AUTOSAR XML (schema 00052)
standard types defined: boolean, float32, float64, sint32, sint16, sint8, uint32, uint16, uint8, void
package /AUTOSAR_Platform/ImplementationDataTypes
  36 x impl type, all with category=VALUE:
    Message1_ChkSum_IDT: base-type=Message1_ChkSum_sw_basetype
    Message1_Alvctr_IDT: base-type=Message1_Alvctr_sw_basetype
    Message1_DID_IDT: base-type=Message1_DID_sw_basetype
    Signal{4..7}_IDT: base-type=Signal{4..7}_sw_basetype
    Message2_ChkSum_IDT: base-type=Message2_ChkSum_sw_basetype
    Message2_Alvctr_IDT: base-type=Message2_Alvctr_sw_basetype
    Message2_DID_IDT: base-type=Message2_DID_sw_basetype
    Signal{8..15}_IDT: base-type=Signal{8..15}_sw_basetype
    Message4_ChkSum_IDT: base-type=Message4_ChkSum_sw_basetype
    Message4_Alvctr_IDT: base-type=Message4_Alvctr_sw_basetype
    Message4_DID_IDT: base-type=Message4_DID_sw_basetype
    Signal{16..19}_IDT: base-type=Signal{16..19}_sw_basetype
    Message5_ChkSum_IDT: base-type=Message5_ChkSum_sw_basetype
    Message5_Alvctr_IDT: base-type=Message5_Alvctr_sw_basetype
    Message5_DID_IDT: base-type=Message5_DID_sw_basetype
    Signal{20..27}_IDT: base-type=Signal{20..27}_sw_basetype
package /AUTOSAR_Platform/MemoryAddressMapping
  4 x sw addr method:
    CALIB: memory-allocation-keyword-policy=ADDR-METHOD-SHORT-NAME-AND-ALIGNMENT, section-type=CALPRM  # SwAddrMethod for normal variables (RAM).
    CODE: memory-allocation-keyword-policy=ADDR-METHOD-SHORT-NAME, section-type=CODE
    CONST: memory-allocation-keyword-policy=ADDR-METHOD-SHORT-NAME-AND-ALIGNMENT, section-type=CONST
    VAR: memory-allocation-keyword-policy=ADDR-METHOD-SHORT-NAME-AND-ALIGNMENT, section-type=VAR
package /System
  system System: category=SYSTEM_DESCRIPTION, system-version=1.0.0
    system mapping SystemMapping
      data-mappings:
        sender-receiver-to-signal-group-mapping={data-element=Core0.Core0_QM.OutputComp.RootSoftwareComposition.PP_Message1.Message1, signal-group=Message1, type-mapping=sender-rec-record-type-mapping=record-element-mappings=[{application-record-element=Message1_ChkSum_ADT, system-signal=Message1_ChkSum}, {application-record-element=Message1_Alvctr_ADT, system-signal=Message1_Alvctr}, {application-record-element=Message1_DID_ADT, system-signal=Message1_DID}, {application-record-element=Signal4_ADT, system-signal=Signal4}, {application-record-element=Signal5_ADT, system-signal=Signal5}, {application-record-element=Signal6_ADT, system-signal=Signal6}, {application-record-element=Signal7_ADT, system-signal=Signal7}]}
        sender-receiver-to-signal-group-mapping={data-element=Core0.Core0_QM.OutputComp.RootSoftwareComposition.PP_Message2.Message2, signal-group=Message2, type-mapping=sender-rec-record-type-mapping=record-element-mappings=[{application-record-element=Message2_ChkSum_ADT, system-signal=Message2_ChkSum}, {application-record-element=Message2_Alvctr_ADT, system-signal=Message2_Alvctr}, {application-record-element=Message2_DID_ADT, system-signal=Message2_DID}, {application-record-element=Signal8_ADT, system-signal=Signal8}, {application-record-element=Signal9_ADT, system-signal=Signal9}, {application-record-element=Signal10_ADT, system-signal=Signal10}, {application-record-element=Signal11_ADT, system-signal=Signal11}]}
        sender-receiver-to-signal-mapping={data-element=Core0.Core0_QM.OutputComp.RootSoftwareComposition.PP_Message3.Signal{12..15}, system-signal=Signal{12..15}}
        sender-receiver-to-signal-group-mapping={data-element=Core0.Core0_QM.InputComp.RootSoftwareComposition.RP_Message4.Message4, signal-group=Message4, type-mapping=sender-rec-record-type-mapping=record-element-mappings=[{application-record-element=Message4_ChkSum_ADT, system-signal=Message4_ChkSum}, {application-record-element=Message4_Alvctr_ADT, system-signal=Message4_Alvctr}, {application-record-element=Message4_DID_ADT, system-signal=Message4_DID}, {application-record-element=Signal16_ADT, system-signal=Signal16}, {application-record-element=Signal17_ADT, system-signal=Signal17}, {application-record-element=Signal18_ADT, system-signal=Signal18}, {application-record-element=Signal19_ADT, system-signal=Signal19}]}
        sender-receiver-to-signal-group-mapping={data-element=Core0.Core0_QM.InputComp.RootSoftwareComposition.RP_Message5.Message5, signal-group=Message5, type-mapping=sender-rec-record-type-mapping=record-element-mappings=[{application-record-element=Message5_ChkSum_ADT, system-signal=Message5_ChkSum}, {application-record-element=Message5_Alvctr_ADT, system-signal=Message5_Alvctr}, {application-record-element=Message5_DID_ADT, system-signal=Message5_DID}, {application-record-element=Signal20_ADT, system-signal=Signal20}, {application-record-element=Signal21_ADT, system-signal=Signal21}, {application-record-element=Signal22_ADT, system-signal=Signal22}, {application-record-element=Signal23_ADT, system-signal=Signal23}]}
        sender-receiver-to-signal-mapping={data-element=Core0.Core0_QM.InputComp.RootSoftwareComposition.RP_Message6.Signal{24..27}, system-signal=Signal{24..27}}
      sw-mappings:
        swc to ecu mapping Core0: component=RootSoftwareComposition.Core0, ecu-instance=ECU1
        swc to ecu mapping Core1: component=RootSoftwareComposition.Core1, ecu-instance=ECU1
    root-software-compositions:
      root sw composition prototype RootSoftwareComposition: software-composition=TopLevelComposition
package /CANInterfaces
  6 x sender receiver interface:
    Message1
      data Message1: type=Message1ADT
    Message2
      data Message2: type=Message2ADT
    Message3
      4 x data, all with sw-addr-method=VAR, sw-calibration-access=READ-ONLY:
        Signal{12..15}: type=Signal{12..15}_ADT
    Message4
      data Message4: type=Message4ADT
    Message5
      data Message5: type=Message5ADT
    Message6
      4 x data, all with sw-addr-method=VAR, sw-calibration-access=READ-ONLY:
        Signal24: type=Signal24_ADT  # Signal23
        Signal25: type=Signal25_ADT  # Signal24
        Signal26: type=Signal26_ADT  # Signal25
        Signal27: type=Signal27_ADT  # Signal26
package /Capgemini_Platform/ImplementationArrayDataTypes
  4 x impl type, all with category=ARRAY:
    uint8_5
      element uint8_5_Columns: array-size=5, array-size-semantics=FIXED-SIZE, implementation-data-type=uint8
    uint8_5_8
      element uint8_5_8_Columns: category=ARRAY, array-size=5, array-size-semantics=FIXED-SIZE
        element uint8_5_8_Rows: array-size=8, array-size-semantics=FIXED-SIZE, implementation-data-type=uint8
    uint32_10
      element uint32_10_Columns: array-size=10, array-size-semantics=FIXED-SIZE, implementation-data-type=uint32
    float32_10_6
      element float32_10_6_Columns: category=ARRAY, array-size=10, array-size-semantics=FIXED-SIZE
        element float32_10_6_Rows: array-size=6, array-size-semantics=FIXED-SIZE, implementation-data-type=float32
package /Capgemini_Platform/ImplementationRecordDataTypes
  6 x impl type, all with category=STRUCTURE:
    test_RecordDatatype
      element ele1: category=ARRAY
        element ele1_Columns: category=ARRAY, array-size=10, array-size-semantics=FIXED-SIZE
          element ele1_Rows: array-size=6, array-size-semantics=FIXED-SIZE, implementation-data-type=float32
      element ele2: category=VALUE, base-type=uint8
      element ele3: category=VALUE, base-type=uint32
    TestDT
      element ImplArrayDT: category=ARRAY
        element ImplArrayDT_Columns: category=ARRAY, array-size=10, array-size-semantics=FIXED-SIZE
          element ImplArrayDT_Rows: array-size=6, array-size-semantics=FIXED-SIZE, implementation-data-type=float32
      element ImplScalarDT: category=VALUE, base-type=uint8
      element test_RecordDatatype: category=STRUCTURE
        element ele1: category=ARRAY
          element ele1_Columns: category=ARRAY, array-size=10, array-size-semantics=FIXED-SIZE
            element ele1_Rows: array-size=6, array-size-semantics=FIXED-SIZE, implementation-data-type=float32
        element ele2: category=VALUE, base-type=uint8
        element ele3: category=VALUE, base-type=uint32
    Message1IDT
      7 x element, all with category=VALUE:
        Message1_ChkSum_IDT: base-type=Message1_ChkSum_sw_basetype
        Message1_Alvctr_IDT: base-type=Message1_Alvctr_sw_basetype
        Message1_DID_IDT: base-type=Message1_DID_sw_basetype
        Signal{4..7}_IDT: base-type=Signal{4..7}_sw_basetype
    Message2IDT
      7 x element, all with category=VALUE:
        Message2_ChkSum_IDT: base-type=Message2_ChkSum_sw_basetype
        Message2_Alvctr_IDT: base-type=Message2_Alvctr_sw_basetype
        Message2_DID_IDT: base-type=Message2_DID_sw_basetype
        Signal{8..11}_IDT: base-type=Signal{8..11}_sw_basetype
    Message4IDT
      7 x element, all with category=VALUE:
        Message4_ChkSum_IDT: base-type=Message4_ChkSum_sw_basetype
        Message4_Alvctr_IDT: base-type=Message4_Alvctr_sw_basetype
        Message4_DID_IDT: base-type=Message4_DID_sw_basetype
        Signal{16..19}_IDT: base-type=Signal{16..19}_sw_basetype
    Message5IDT
      7 x element, all with category=VALUE:
        Message5_ChkSum_IDT: base-type=Message5_ChkSum_sw_basetype
        Message5_Alvctr_IDT: base-type=Message5_Alvctr_sw_basetype
        Message5_DID_IDT: base-type=Message5_DID_sw_basetype
        Signal{20..23}_IDT: base-type=Signal{20..23}_sw_basetype
package /Capgemini_Platform/CompuMethods
  compu method Compu_TextTable: 0=Yes, 1=No
package /Capgemini_Platform/DataConstraints
  range DC_0_5: raw 0..5
package /Capgemini_Platform/Units
  41 x unit, all with factor-si-to-unit=1:
    NoUnit: display-name=Nounit  # Unit for dimensionless continuous value data types like numbers, factors, and coefficients
    Volt: display-name=V  # Voltage
    Current: display-name=A
    DegreeCelcius: display-name=°C  # Celcius
    DegreeFahrenheit: display-name=°F  # Fahrenheit
    Percentage: display-name=%
    Message1_Alvctr_Unit: display-name=NoUnit  # NoUnit
    Message1_DID_Unit: display-name=NoUnit  # NoUnit
    Signal4_Unit: display-name=V  # Voltage
    Signal5_Unit: display-name=A  # Current
    Signal6_Unit: display-name=°C  # Celcius
    Signal7_Unit: display-name=°F  # Fahrenheit
    Message2_ChkSum_Unit: display-name=NoUnit  # NoUnit
    Message2_Alvctr_Unit: display-name=NoUnit  # NoUnit
    Message2_DID_Unit: display-name=NoUnit  # NoUnit
    Signal8_Unit: display-name=V  # Voltage
    Signal9_Unit: display-name=A  # Current
    Signal10_Unit: display-name=°C  # Celcius
    Signal11_Unit: display-name=°F  # Fahrenheit
    Signal12_Unit: display-name=V  # Voltage
    Signal13_Unit: display-name=A  # Current
    Signal14_Unit: display-name=°C  # Celcius
    Signal15_Unit: display-name=°F  # Fahrenheit
    Message4_ChkSum_Unit: display-name=NoUnit  # NoUnit
    Message4_Alvctr_Unit: display-name=NoUnit  # NoUnit
    Message4_DID_Unit: display-name=NoUnit  # NoUnit
    Signal16_Unit: display-name=V  # Voltage
    Signal17_Unit: display-name=A  # Current
    Signal18_Unit: display-name=°C  # Celcius
    Signal19_Unit: display-name=°F  # Fahrenheit
    Message5_ChkSum_Unit: display-name=NoUnit  # NoUnit
    Message5_Alvctr_Unit: display-name=NoUnit  # NoUnit
    Message5_DID_Unit: display-name=NoUnit  # NoUnit
    Signal20_Unit: display-name=V  # Voltage
    Signal21_Unit: display-name=A  # Current
    Signal22_Unit: display-name=°C  # Celcius
    Signal23_Unit: display-name=°F  # Fahrenheit
    Signal24_Unit: display-name=V  # Voltage
    Signal25_Unit: display-name=A  # Current
    Signal26_Unit: display-name=°C  # Celcius
    Signal27_Unit: display-name=°F  # Fahrenheit
package /Capgemini_Platform/ApplicationDataTypes
  app type Element1_ADT: category=VALUE, sw-calibration-access=READ-WRITE, compu {phys=raw*5+0.5}, range raw 0..255, unit=A
  app type Element3_ADT: category=VALUE, sw-calibration-access=READ-WRITE, compu {phys=raw*5+0.5}, range raw 0..255, unit=A
  application array data type Element3_ADT_Columns: category=ARRAY
    element Element: category=VALUE, type=Element3_ADT_Rows, array-size-semantics=FIXED-SIZE, max-number-of-elements=5
  application array data type Element3_ADT_Rows: category=ARRAY
    element Element: category=VALUE, type=Element3_ADT, array-size-semantics=FIXED-SIZE, max-number-of-elements=8
  app type Element2_ADT: category=VALUE, sw-calibration-access=READ-WRITE, compu {phys=raw*5+0.5}, range raw 0..255, unit=A
  application array data type Element2_ADT_Columns: category=ARRAY
    element Element: category=VALUE, type=Element2_ADT_Rows, array-size-semantics=FIXED-SIZE, max-number-of-elements=5
  application array data type Element2_ADT_Rows: category=ARRAY
    element Element: category=VALUE, type=Element2_ADT, array-size-semantics=FIXED-SIZE, max-number-of-elements=8
  app type Element4_ADT: category=VALUE, sw-calibration-access=READ-WRITE, compu {phys=raw*5+0.5}, range raw 0..255, unit=A
  application array data type Element4_ADT_Columns: category=ARRAY
    element Element: category=VALUE, type=Element4_ADT_Rows, array-size-semantics=FIXED-SIZE, max-number-of-elements=5
  application array data type Element4_ADT_Rows: category=ARRAY
    element Element: category=VALUE, type=Element4_ADT, array-size-semantics=FIXED-SIZE, max-number-of-elements=8
  app type Element5_ADT: category=VALUE, sw-calibration-access=READ-WRITE, compu {phys=raw*5+0.5}, range raw 0..255, unit=A
  application array data type Element5_ADT_Columns: category=ARRAY
    element Element: category=VALUE, type=Element5_ADT_Rows, array-size-semantics=FIXED-SIZE, max-number-of-elements=5
  application array data type Element5_ADT_Rows: category=ARRAY
    element Element: category=VALUE, type=Element5_ADT, array-size-semantics=FIXED-SIZE, max-number-of-elements=8
  17 x app type, all with category=VALUE:
    Cureent_ADT: sw-calibration-access=READ-WRITE, compu {identical}, range raw 0..100, unit=A
    CANData_1_ADT: sw-calibration-access=READ-WRITE, compu {phys=0.01}, range raw 0..1, unit=%
    Current_ADT: sw-calibration-access=READ-WRITE, compu {identical}, range raw -3.4e+38..3.4e+38, unit=A
    Voltage_ADT: sw-calibration-access=READ-WRITE, compu {identical}, range raw -3.4e+38..3.4e+38, unit=V
    Cell_Voltage_ADT: sw-calibration-access=READ-WRITE, compu {identical}, range raw -3.4e+38..3.4e+38
    Current_Avg_ADT: sw-calibration-access=READ-WRITE, compu {identical}, range raw -3.4e+38..3.4e+38
    Voltage_OC_ADT: sw-calibration-access=READ-WRITE, compu {identical}, range raw -3.4e+38..3.4e+38
    Ccounter_NVStateOfCharge_ADT: sw-calibration-access=READ-WRITE, compu {identical}, range raw 0..255
    RecalSOC_NVStateOfCharge_ADT: sw-calibration-access=READ-WRITE, compu {identical}, range raw 0..255
    Op1Arg{1..3}_ADT: sw-calibration-access=READ-WRITE, compu {identical}, range raw 0..65535, unit=A
    Op2Arg{1..3}_ADT: sw-calibration-access=READ-WRITE, compu {identical}, range raw 0..65535, unit=A
    Param1_ADT: sw-calibration-access=READ-ONLY, compu {identical}, range raw 0..65535, unit=A
    Param2_ADT: sw-calibration-access=READ-WRITE, compu {identical}, range raw 0..4294967295, unit=A
  application array data type Param2_ADT_Columns: category=ARRAY
    element Element: category=VALUE, type=Param2_ADT, array-size-semantics=FIXED-SIZE, max-number-of-elements=10
  app type InputCompCANParam_ADT: category=VALUE, sw-calibration-access=READ-ONLY, compu {identical}, range raw 0..65535, unit=%
  application record data type ParamWithRecordDT_ADT: category=STRUCTURE, sw-calibration-access=READ-ONLY
    application record element ImplArrayDT: type=ImplArrayDT_ADT_Columns
    application record element ImplScalarDT: type=ImplScalarDT_ADT
    application record element test_RecordDatatype: type=test_RecordDatatype_ADT
  app type ImplArrayDT_ADT: category=VALUE, sw-calibration-access=READ-ONLY, compu {identical}, range raw -3.4e+38..3.4e+38, unit=V
  application array data type ImplArrayDT_ADT_Columns: category=ARRAY
    element Element: category=VALUE, type=ImplArrayDT_ADT_Rows, array-size-semantics=FIXED-SIZE, max-number-of-elements=10
  application array data type ImplArrayDT_ADT_Rows: category=ARRAY
    element Element: category=VALUE, type=ImplArrayDT_ADT, array-size-semantics=FIXED-SIZE, max-number-of-elements=6
  app type ImplScalarDT_ADT: category=VALUE, sw-calibration-access=READ-ONLY, compu {identical}, range raw 0..255, unit=V
  application record data type test_RecordDatatype_ADT: category=STRUCTURE, sw-calibration-access=READ-ONLY
    application record element ele1: type=ele1_ADT_Columns
    application record element ele2: type=ele2_ADT
    application record element ele3: type=ele3_ADT
  app type ele1_ADT: category=VALUE, sw-calibration-access=READ-ONLY, compu {identical}, range raw -3.4e+38..3.4e+38, unit=V
  application array data type ele1_ADT_Columns: category=ARRAY
    element Element: category=VALUE, type=ele1_ADT_Rows, array-size-semantics=FIXED-SIZE, max-number-of-elements=10
  application array data type ele1_ADT_Rows: category=ARRAY
    element Element: category=VALUE, type=ele1_ADT, array-size-semantics=FIXED-SIZE, max-number-of-elements=6
  12 x app type, all with category=VALUE, compu {identical}:
    ele2_ADT: sw-calibration-access=READ-ONLY, range raw 0..255, unit=V
    ele3_ADT: sw-calibration-access=READ-ONLY, range raw 0..4294967295, unit=V
    nominalCapacity_C_ADT: sw-calibration-access=READ-ONLY, range raw -3.4e+38..3.4e+38
    stateOfHealth_C_ADT: sw-calibration-access=READ-ONLY, range raw -3.4e+38..3.4e+38
    stateOfCharge_C_ADT: sw-calibration-access=READ-ONLY, range raw -3.4e+38..3.4e+38
    OCV_gra_C_ADT: sw-calibration-access=READ-ONLY, range raw -3.4e+38..3.4e+38
    IRV1_ADT: sw-calibration-access=READ-WRITE, range raw -32768..32767, unit=V
    IRV2_ADT: sw-calibration-access=READ-WRITE, range raw -3.4e+38..3.4e+38
    InputCompCAN_IRV_ADT: sw-calibration-access=READ-ONLY, range raw -3.4e+38..3.4e+38, unit=%
    PIM_Element1_ADT: sw-calibration-access=READ-WRITE, range raw -32768..32767, unit=V
    InputCompPIM_ADT: sw-calibration-access=READ-ONLY, range raw -32768..32767, unit=%
    StateOfHealth_ADT: sw-calibration-access=READ-WRITE, range raw 0..255
  application record data type Message1ADT: category=STRUCTURE, sw-calibration-access=READ-ONLY
    7 x application record element:
      Message1_ChkSum_ADT: type=Message1_ChkSum_ADT
      Message1_Alvctr_ADT: type=Message1_Alvctr_ADT
      Message1_DID_ADT: type=Message1_DID_ADT
      Signal{4..7}_ADT: type=Signal{4..7}_ADT
  7 x app type, all with category=VALUE, sw-calibration-access=READ-ONLY:
    Message1_ChkSum_ADT: compu {phys=raw*10+10}, range raw 0..50
    Message1_Alvctr_ADT: compu {phys=0.5}, range raw -100..100, unit=NoUnit
    Message1_DID_ADT: compu {phys=2}, range raw 0..1000, unit=NoUnit
    Signal4_ADT: compu {phys=raw*100+1}, range raw -5000..5000, unit=V
    Signal5_ADT: compu {identical}, range raw 0..100, unit=A
    Signal6_ADT: compu {identical}, range raw 0..100, unit=°C
    Signal7_ADT: compu {identical}, range raw 0..5000, unit=°F
  application record data type Message2ADT: category=STRUCTURE, sw-calibration-access=READ-ONLY
    7 x application record element:
      Message2_ChkSum_ADT: type=Message2_ChkSum_ADT
      Message2_Alvctr_ADT: type=Message2_Alvctr_ADT
      Message2_DID_ADT: type=Message2_DID_ADT
      Signal{8..11}_ADT: type=Signal{8..11}_ADT
  11 x app type, all with category=VALUE, sw-calibration-access=READ-ONLY:
    Message2_ChkSum_ADT: compu {phys=raw*10+10}, range raw 0..50, unit=NoUnit
    Message2_Alvctr_ADT: compu {phys=0.5}, range raw -100..100, unit=NoUnit
    Message2_DID_ADT: compu {phys=2}, range raw 0..1000, unit=NoUnit
    Signal8_ADT: compu {phys=raw*100+1}, range raw -5000..5000, unit=V
    Signal9_ADT: compu {identical}, range raw 0..100, unit=A
    Signal10_ADT: compu {identical}, range raw 0..100, unit=°C
    Signal11_ADT: compu {identical}, range raw 0..5000, unit=°F
    Signal12_ADT: compu {phys=raw*100+1}, range raw -5000..5000, unit=V
    Signal13_ADT: compu {identical}, range raw 0..100, unit=A
    Signal14_ADT: compu {identical}, range raw 0..100, unit=°C
    Signal15_ADT: compu {identical}, range raw 0..5000, unit=°F
  application record data type Message4ADT: category=STRUCTURE, sw-calibration-access=READ-ONLY
    7 x application record element:
      Message4_ChkSum_ADT: type=Message4_ChkSum_ADT
      Message4_Alvctr_ADT: type=Message4_Alvctr_ADT
      Message4_DID_ADT: type=Message4_DID_ADT
      Signal{16..19}_ADT: type=Signal{16..19}_ADT
  7 x app type, all with category=VALUE, sw-calibration-access=READ-ONLY:
    Message4_ChkSum_ADT: compu {phys=raw*10+10}, range raw 0..50, unit=NoUnit
    Message4_Alvctr_ADT: compu {phys=0.5}, range raw -100..100, unit=NoUnit
    Message4_DID_ADT: compu {phys=2}, range raw 0..1000, unit=NoUnit
    Signal16_ADT: compu {phys=raw*100+1}, range raw -5000..5000, unit=V
    Signal17_ADT: compu {identical}, range raw 0..100, unit=A
    Signal18_ADT: compu {identical}, range raw 0..100, unit=°C
    Signal19_ADT: compu {identical}, range raw 0..5000, unit=°F
  application record data type Message5ADT: category=STRUCTURE, sw-calibration-access=READ-ONLY
    7 x application record element:
      Message5_ChkSum_ADT: type=Message5_ChkSum_ADT
      Message5_Alvctr_ADT: type=Message5_Alvctr_ADT
      Message5_DID_ADT: type=Message5_DID_ADT
      Signal{20..23}_ADT: type=Signal{20..23}_ADT
  11 x app type, all with category=VALUE, sw-calibration-access=READ-ONLY:
    Message5_ChkSum_ADT: compu {phys=raw*10+10}, range raw 0..50, unit=NoUnit
    Message5_Alvctr_ADT: compu {phys=0.5}, range raw -100..100, unit=NoUnit
    Message5_DID_ADT: compu {phys=2}, range raw 0..1000, unit=NoUnit
    Signal20_ADT: compu {phys=raw*100+1}, range raw -5000..5000, unit=V
    Signal21_ADT: compu {identical}, range raw 0..100, unit=A
    Signal22_ADT: compu {identical}, range raw 0..100, unit=°C
    Signal23_ADT: compu {identical}, range raw 0..5000, unit=°F
    Signal24_ADT: compu {phys=raw*100+1}, range raw -5000..5000, unit=V
    Signal25_ADT: compu {identical}, range raw 0..100, unit=A
    Signal26_ADT: compu {identical}, range raw 0..100, unit=°C
    Signal27_ADT: compu {identical}, range raw 0..5000, unit=°F
package /Capgemini_Platform/InitValues
  13 x constant specification:
    Param1: value-spec=0 A
    Param2: value-spec=10 x 0 A
    InputCompCANParam: value-spec=50 %
    nominalCapacity_C: value-spec=0
    stateOfHealth_C: value-spec=0
    stateOfCharge_C: value-spec=0
    OCV_gra_C: value-spec=0
    IRV1: value-spec=0 V
    IRV2: value-spec=0
    InputCompCAN_IRV: value-spec=0 %
    PIM_Element1: value-spec=0 V
    InputCompPIM: value-spec=0 %
    StateOfHealth: value-spec=0
package /Capgemini_Platform/DataTypeMappingSet
  data type mapping set DataTypeMappingSet
    data-type-maps:
      application-data-type=Element1_ADT, implementation-data-type=uint8
      application-data-type=Element3_ADT_Columns, implementation-data-type=uint8_5_8
      application-data-type=Element2_ADT_Columns, implementation-data-type=uint8_5_8
      application-data-type=Element4_ADT_Columns, implementation-data-type=uint8_5_8
      application-data-type=Element5_ADT_Columns, implementation-data-type=uint8_5_8
      application-data-type=Cureent_ADT, implementation-data-type=float32
      application-data-type=CANData_1_ADT, implementation-data-type=uint8
      application-data-type=Current_ADT, implementation-data-type=float32
      application-data-type=Voltage_ADT, implementation-data-type=float32
      application-data-type=Cell_Voltage_ADT, implementation-data-type=float32
      application-data-type=Current_Avg_ADT, implementation-data-type=float32
      application-data-type=Voltage_OC_ADT, implementation-data-type=float32
      application-data-type=Ccounter_NVStateOfCharge_ADT, implementation-data-type=uint8
      application-data-type=RecalSOC_NVStateOfCharge_ADT, implementation-data-type=uint8
      application-data-type=Op1Arg{1..3}_ADT, implementation-data-type=uint16
      application-data-type=Op2Arg{1..3}_ADT, implementation-data-type=uint16
      application-data-type=Param1_ADT, implementation-data-type=uint16
      application-data-type=Param2_ADT_Columns, implementation-data-type=uint32_10
      application-data-type=InputCompCANParam_ADT, implementation-data-type=uint16
      application-data-type=ImplArrayDT_ADT_Columns, implementation-data-type=float32_10_6
      application-data-type=ImplScalarDT_ADT, implementation-data-type=uint8
      application-data-type=ele1_ADT_Columns, implementation-data-type=float32_10_6
      application-data-type=ele2_ADT, implementation-data-type=uint8
      application-data-type=ele3_ADT, implementation-data-type=uint32
      application-data-type=test_RecordDatatype_ADT, implementation-data-type=test_RecordDatatype
      application-data-type=ParamWithRecordDT_ADT, implementation-data-type=TestDT
      application-data-type=nominalCapacity_C_ADT, implementation-data-type=float32
      application-data-type=stateOfHealth_C_ADT, implementation-data-type=float32
      application-data-type=stateOfCharge_C_ADT, implementation-data-type=float32
      application-data-type=OCV_gra_C_ADT, implementation-data-type=float32
      application-data-type=IRV1_ADT, implementation-data-type=sint16
      application-data-type=IRV2_ADT, implementation-data-type=float32
      application-data-type=InputCompCAN_IRV_ADT, implementation-data-type=float32
      application-data-type=PIM_Element1_ADT, implementation-data-type=sint16
      application-data-type=InputCompPIM_ADT, implementation-data-type=sint16
      application-data-type=StateOfHealth_ADT, implementation-data-type=uint8
      application-data-type=Message1ADT, implementation-data-type=Message1IDT
      application-data-type=Message1_ChkSum_ADT, implementation-data-type=Message1_ChkSum_IDT
      application-data-type=Message1_Alvctr_ADT, implementation-data-type=Message1_Alvctr_IDT
      application-data-type=Message1_DID_ADT, implementation-data-type=Message1_DID_IDT
      application-data-type=Signal{4..7}_ADT, implementation-data-type=Signal{4..7}_IDT
      application-data-type=Message2ADT, implementation-data-type=Message2IDT
      application-data-type=Message2_ChkSum_ADT, implementation-data-type=Message2_ChkSum_IDT
      application-data-type=Message2_Alvctr_ADT, implementation-data-type=Message2_Alvctr_IDT
      application-data-type=Message2_DID_ADT, implementation-data-type=Message2_DID_IDT
      application-data-type=Signal{8..15}_ADT, implementation-data-type=Signal{8..15}_IDT
      application-data-type=Message4ADT, implementation-data-type=Message4IDT
      application-data-type=Message4_ChkSum_ADT, implementation-data-type=Message4_ChkSum_IDT
      application-data-type=Message4_Alvctr_ADT, implementation-data-type=Message4_Alvctr_IDT
      application-data-type=Message4_DID_ADT, implementation-data-type=Message4_DID_IDT
      application-data-type=Signal{16..19}_ADT, implementation-data-type=Signal{16..19}_IDT
      application-data-type=Message5ADT, implementation-data-type=Message5IDT
      application-data-type=Message5_ChkSum_ADT, implementation-data-type=Message5_ChkSum_IDT
      application-data-type=Message5_Alvctr_ADT, implementation-data-type=Message5_Alvctr_IDT
      application-data-type=Message5_DID_ADT, implementation-data-type=Message5_DID_IDT
      application-data-type=Signal{20..27}_ADT, implementation-data-type=Signal{20..27}_IDT
package /Root_Package/SWCs/Core0/QM/CompA
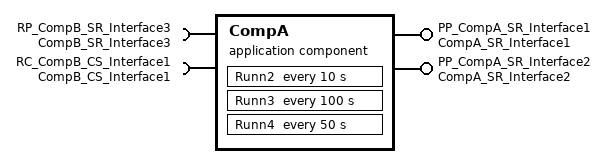
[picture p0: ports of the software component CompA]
  application sw component type CompA
    provide port PP_CompA_SR_Interface1: provided-interface=CompA_SR_Interface1
    provide port PP_CompA_SR_Interface2: provided-interface=CompA_SR_Interface2
    require port RP_CompB_SR_Interface3: required-interface=CompB_SR_Interface3
    require port RC_CompB_CS_Interface1: required-interface=CompB_CS_Interface1
    behavior CompA_InternalBehavior: data-type-mapping=DataTypeMappingSet, handle-termination-and-restart=NO-SUPPORT
      ar-typed-per-instance-memorys:
        data PIM_Element1: sw-addr-method=CALIB, sw-calibration-access=READ-WRITE, type=PIM_Element1_ADT, init-value=constant-reference=PIM_Element1  # Test1
      init event Runn1_InitEvent: start-on-event=Runn1
      timing event Runn2_TimingEvent_10ms: start-on-event=Runn2, period=10
      timing event Runn3_TimingEvent_100ms: start-on-event=Runn3, period=100
      timing event Runn4_TimingEvent_50ms: start-on-event=Runn4, period=50
      explicit-inter-runnable-variables:
        data IRV1: sw-addr-method=VAR, sw-calibration-access=READ-WRITE, type=IRV1_ADT, init-value=constant-reference=IRV1  # Test2
      per-instance-parameters:
        parameter data prototype Param1: sw-addr-method=CONST, sw-calibration-access=READ-ONLY, type=Param1_ADT, init-value=constant-reference=Param1  # ParamDesc1
        parameter data prototype Param2: sw-addr-method=CONST, sw-calibration-access=READ-WRITE, type=Param2_ADT_Columns, init-value=constant-reference=Param2  # ParamDesc2
      4 x runnable, all with sw-addr-method=CODE:
        Runn1: symbol=CompA_Runn1
        Runn2: symbol=CompA_Runn2
          data-read-access:
            access DRA_RP_CompB_SR_Interface3_Element4: accessed-variable=RP_CompB_SR_Interface3.Element4
          data-send-points:
            access DSP_PP_CompA_SR_Interface1_Element1: accessed-variable=PP_CompA_SR_Interface1.Element1
            access DSP_PP_CompA_SR_Interface1_Element3: accessed-variable=PP_CompA_SR_Interface1.Element3
            access DSP_PP_CompA_SR_Interface2_Element2: accessed-variable=PP_CompA_SR_Interface2.Element2
          parameter access PIPA_Param1: accessed-parameter=Param1
          parameter access PIPA_Param2: accessed-parameter=Param2
          written-local-variables:
            access IRVWA_IRV1: accessed-variable=IRV1
        Runn3: symbol=CompA_Runn3
          data-read-access:
            access DRA_RP_CompB_SR_Interface3_Element4: accessed-variable=RP_CompB_SR_Interface3.Element4
          data-send-points:
            access DSP_PP_CompA_SR_Interface2_Element2: accessed-variable=PP_CompA_SR_Interface2.Element2
          parameter access PIPA_Param1: accessed-parameter=Param1
          read-local-variables:
            access IRVRA_IRV1: accessed-variable=IRV1
          async call Operation2: operation=RC_CompB_CS_Interface1.Operation2, timeout=0
        Runn4: symbol=CompA_Runn4
          data-send-points:
            access DSP_PP_CompA_SR_Interface1_Element1: accessed-variable=PP_CompA_SR_Interface1.Element1
          sync call Operation1: operation=RC_CompB_CS_Interface1.Operation1, timeout=0
          async call Operation2: operation=RC_CompB_CS_Interface1.Operation2, timeout=0
  swc implementation CompA_Implementation: programming-language=C, sw-version=1.0.0, vendor-id=100, behavior=CompA_InternalBehavior
    code-descriptors:
      code CompA_CodeDescriptor: artifact-descriptors=autosar-engineering-object={short-label=CompA, category=SWSRC}
    resource consumption CompA_RC
      13 x memory section:
        VAR_8: alignment=8, sw-addrmethod=VAR
        VAR_16: alignment=16, sw-addrmethod=VAR
        VAR_32: alignment=32, sw-addrmethod=VAR
        VAR_UNSPECIFIED: sw-addrmethod=VAR
        CALIB_8: alignment=8, sw-addrmethod=CALIB
        CALIB_16: alignment=16, sw-addrmethod=CALIB
        CALIB_32: alignment=32, sw-addrmethod=CALIB
        CALIB_UNSPECIFIED: sw-addrmethod=CALIB
        CONST_8: alignment=8, sw-addrmethod=CONST
        CONST_16: alignment=16, sw-addrmethod=CONST
        CONST_32: alignment=32, sw-addrmethod=CONST
        CONST_UNSPECIFIED: sw-addrmethod=CONST
        CODE: sw-addrmethod=CODE
package /Root_Package/SWCs/Core0/QM/CompA/CompA_SRInterfaces
  sender receiver interface CompA_SR_Interface1
    data Element1: sw-addr-method=VAR, sw-calibration-access=READ-WRITE, type=Element1_ADT  # asd
    data Element3: sw-addr-method=VAR, sw-calibration-access=READ-WRITE, type=Element3_ADT_Columns  # Test4
  sender receiver interface CompA_SR_Interface2
    data Element2: sw-addr-method=VAR, sw-calibration-access=READ-WRITE, type=Element2_ADT_Columns  # Test3
package /Root_Package/SWCs/Core0/QM/CompB
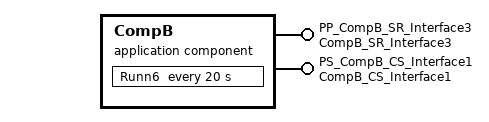
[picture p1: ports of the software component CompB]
  application sw component type CompB
    provide port PP_CompB_SR_Interface3: provided-interface=CompB_SR_Interface3
    provide port PS_CompB_CS_Interface1: provided-interface=CompB_CS_Interface1
    behavior CompB_InternalBehavior: data-type-mapping=DataTypeMappingSet, handle-termination-and-restart=NO-SUPPORT
      init event Runn5_InitEvent: start-on-event=Runn5
      timing event Runn6_TimingEvent_20ms: start-on-event=Runn6, period=20
      operation invoked event OIE_Runn7: start-on-event=Runn7, operation=PS_CompB_CS_Interface1.Operation1
      operation invoked event OIE_Runn15: start-on-event=Runn15, operation=PS_CompB_CS_Interface1.Operation2
      explicit-inter-runnable-variables:
        data IRV2: sw-addr-method=VAR, sw-calibration-access=READ-WRITE, type=IRV2_ADT, init-value=constant-reference=IRV2  # Test3
      per-instance-parameters:
        parameter data prototype ParamWithRecordDT: sw-addr-method=CONST, sw-calibration-access=READ-ONLY, type=ParamWithRecordDT_ADT  # ParamWithRecordDT_Description
      4 x runnable:
        Runn5: sw-addr-method=CODE, symbol=CompB_Runn5
          parameter access PIPA_ParamWithRecordDT: accessed-parameter=ParamWithRecordDT
          written-local-variables:
            access IRVWA_IRV2: accessed-variable=IRV2
        Runn6: sw-addr-method=CODE, symbol=CompB_Runn6
          data-write-access:
            access DWA_PP_CompB_SR_Interface3_Element4: accessed-variable=PP_CompB_SR_Interface3.Element4
          read-local-variables:
            access IRVRA_IRV2: accessed-variable=IRV2
        Runn7: symbol=CompB_Runn7
        Runn15: symbol=CompB_Runn15
  swc implementation CompB_Implementation: programming-language=C, sw-version=1.0.0, vendor-id=100, behavior=CompB_InternalBehavior
    code-descriptors:
      code CompB_CodeDescriptor: artifact-descriptors=autosar-engineering-object={short-label=CompB, category=SWSRC}
    resource consumption CompB_RC
      13 x memory section:
        VAR_8: alignment=8, sw-addrmethod=VAR
        VAR_16: alignment=16, sw-addrmethod=VAR
        VAR_32: alignment=32, sw-addrmethod=VAR
        VAR_UNSPECIFIED: sw-addrmethod=VAR
        CALIB_8: alignment=8, sw-addrmethod=CALIB
        CALIB_16: alignment=16, sw-addrmethod=CALIB
        CALIB_32: alignment=32, sw-addrmethod=CALIB
        CALIB_UNSPECIFIED: sw-addrmethod=CALIB
        CONST_8: alignment=8, sw-addrmethod=CONST
        CONST_16: alignment=16, sw-addrmethod=CONST
        CONST_32: alignment=32, sw-addrmethod=CONST
        CONST_UNSPECIFIED: sw-addrmethod=CONST
        CODE: sw-addrmethod=CODE
package /Root_Package/SWCs/Core0/QM/CompB/CompB_SRInterfaces
  sender receiver interface CompB_SR_Interface3
    data Element4: sw-addr-method=VAR, sw-calibration-access=READ-WRITE, type=Element4_ADT_Columns  # Test5
package /Root_Package/SWCs/Core0/QM/CompB/CompB_CSInterfaces
  client server interface CompB_CS_Interface1
    operation Operation1
      arg Op1Arg1: type=Op1Arg1_ADT, direction=IN
      arg Op1Arg2: type=Op1Arg2_ADT, direction=OUT
      arg Op1Arg3: type=Op1Arg3_ADT, direction=INOUT
    operation Operation2
      arg Op2Arg1: type=Op2Arg1_ADT, direction=IN  # Op1Arg1
      arg Op2Arg2: type=Op2Arg2_ADT, direction=OUT  # Op1Arg2
      arg Op2Arg3: type=Op2Arg3_ADT, direction=INOUT  # Op1Arg3
package /Root_Package/SWCs/Core0/QM/InputComp
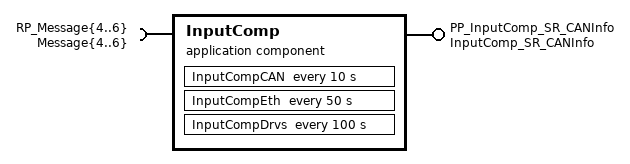
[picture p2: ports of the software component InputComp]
  application sw component type InputComp
    provide port PP_InputComp_SR_CANInfo: provided-interface=InputComp_SR_CANInfo
    require port RP_Message{4..6}: required-interface=Message{4..6}
    behavior InputComp_InternalBehavior: data-type-mapping=DataTypeMappingSet, handle-termination-and-restart=NO-SUPPORT
      ar-typed-per-instance-memorys:
        data InputCompPIM: sw-addr-method=CALIB, sw-calibration-access=READ-ONLY, type=InputCompPIM_ADT, init-value=constant-reference=InputCompPIM  # InputCompPIM_Description
      timing event InputCompCAN_TimingEvent_10ms: start-on-event=InputCompCAN, period=10
      timing event InputCompEth_TimingEvent_50ms: start-on-event=InputCompEth, period=50
      timing event InputCompDrvs_TimingEvent_100ms: start-on-event=InputCompDrvs, period=100
      init event InputCompInit_InitEvent: start-on-event=InputCompInit
      explicit-inter-runnable-variables:
        data InputCompCAN_IRV: sw-addr-method=VAR, sw-calibration-access=READ-ONLY, type=InputCompCAN_IRV_ADT, init-value=constant-reference=InputCompCAN_IRV  # InputCompCAN_IRV_Descriotion
      per-instance-parameters:
        parameter data prototype InputCompCANParam: sw-addr-method=CONST, sw-calibration-access=READ-ONLY, type=InputCompCANParam_ADT, init-value=constant-reference=InputCompCANParam  # InputCompCANParam_Decription
      4 x runnable, all with sw-addr-method=CODE:
        InputCompCAN: symbol=InputComp_InputCompCAN
          data-receive-point-by-arguments:
            6 x access:
              DRP_RP_Message4_Message4: accessed-variable=RP_Message4.Message4
              DRP_RP_Message5_Message5: accessed-variable=RP_Message5.Message5
              DRP_RP_Message6_Signal{24..27}: accessed-variable=RP_Message6.Signal{24..27}
          data-send-points:
            access DSP_PP_InputComp_SR_CANInfo_CANData_1: accessed-variable=PP_InputComp_SR_CANInfo.CANData_1
          parameter access PIPA_InputCompCANParam: accessed-parameter=InputCompCANParam
          written-local-variables:
            access IRVWA_InputCompCAN_IRV: accessed-variable=InputCompCAN_IRV
        InputCompEth: symbol=InputComp_InputCompEth
        InputCompDrvs: symbol=InputComp_InputCompDrvs
          read-local-variables:
            access IRVRA_InputCompCAN_IRV: accessed-variable=InputCompCAN_IRV
        InputCompInit: symbol=InputComp_InputCompInit
  swc implementation InputComp_Implementation: programming-language=C, sw-version=1.0.0, vendor-id=100, behavior=InputComp_InternalBehavior
    code-descriptors:
      code InputComp_CodeDescriptor: artifact-descriptors=autosar-engineering-object={short-label=InputComp, category=SWSRC}
    resource consumption InputComp_RC
      13 x memory section:
        VAR_8: alignment=8, sw-addrmethod=VAR
        VAR_16: alignment=16, sw-addrmethod=VAR
        VAR_32: alignment=32, sw-addrmethod=VAR
        VAR_UNSPECIFIED: sw-addrmethod=VAR
        CALIB_8: alignment=8, sw-addrmethod=CALIB
        CALIB_16: alignment=16, sw-addrmethod=CALIB
        CALIB_32: alignment=32, sw-addrmethod=CALIB
        CALIB_UNSPECIFIED: sw-addrmethod=CALIB
        CONST_8: alignment=8, sw-addrmethod=CONST
        CONST_16: alignment=16, sw-addrmethod=CONST
        CONST_32: alignment=32, sw-addrmethod=CONST
        CONST_UNSPECIFIED: sw-addrmethod=CONST
        CODE: sw-addrmethod=CODE
package /Root_Package/SWCs/Core0/QM/InputComp/InputComp_SRInterfaces
  sender receiver interface InputComp_SR_CANInfo
    data CANData_1: sw-addr-method=VAR, sw-calibration-access=READ-WRITE, type=CANData_1_ADT  # CANData_1_Description
package /Root_Package/SWCs/Core0/QM/OutputComp
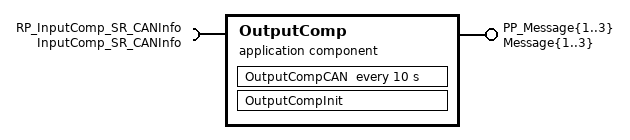
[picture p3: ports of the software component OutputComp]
  application sw component type OutputComp
    require port RP_InputComp_SR_CANInfo: required-interface=InputComp_SR_CANInfo
    provide port PP_Message{1..3}: provided-interface=Message{1..3}
    behavior OutputComp_InternalBehavior: data-type-mapping=DataTypeMappingSet, handle-termination-and-restart=NO-SUPPORT
      timing event OutputCompCAN_TimingEvent_10ms: start-on-event=OutputCompCAN, period=10
      init event OutputCompInit_InitEvent: start-on-event=OutputCompInit
      runnable OutputCompCAN: sw-addr-method=CODE, symbol=OutputComp_OutputCompCAN
        data-receive-point-by-arguments:
          access DRP_RP_InputComp_SR_CANInfo_CANData_1: accessed-variable=RP_InputComp_SR_CANInfo.CANData_1
        data-send-points:
          6 x access:
            DSP_PP_Message1_Message1: accessed-variable=PP_Message1.Message1
            DSP_PP_Message2_Message2: accessed-variable=PP_Message2.Message2
            DSP_PP_Message3_Signal{12..15}: accessed-variable=PP_Message3.Signal{12..15}
      runnable OutputCompInit: sw-addr-method=CODE, symbol=OutputComp_OutputCompInit
  swc implementation OutputComp_Implementation: programming-language=C, sw-version=1.0.0, vendor-id=100, behavior=OutputComp_InternalBehavior
    code-descriptors:
      code OutputComp_CodeDescriptor: artifact-descriptors=autosar-engineering-object={short-label=OutputComp, category=SWSRC}
    resource consumption OutputComp_RC
      13 x memory section:
        VAR_8: alignment=8, sw-addrmethod=VAR
        VAR_16: alignment=16, sw-addrmethod=VAR
        VAR_32: alignment=32, sw-addrmethod=VAR
        VAR_UNSPECIFIED: sw-addrmethod=VAR
        CALIB_8: alignment=8, sw-addrmethod=CALIB
        CALIB_16: alignment=16, sw-addrmethod=CALIB
        CALIB_32: alignment=32, sw-addrmethod=CALIB
        CALIB_UNSPECIFIED: sw-addrmethod=CALIB
        CONST_8: alignment=8, sw-addrmethod=CONST
        CONST_16: alignment=16, sw-addrmethod=CONST
        CONST_32: alignment=32, sw-addrmethod=CONST
        CONST_UNSPECIFIED: sw-addrmethod=CONST
        CODE: sw-addrmethod=CODE
package /Root_Package/SWCs/Core0/QM/Ccounter
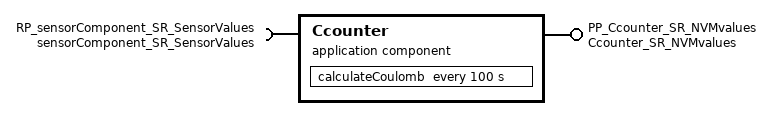
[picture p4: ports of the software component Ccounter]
  application sw component type Ccounter
    provide port PP_Ccounter_SR_NVMvalues: provided-interface=Ccounter_SR_NVMvalues
    require port RP_sensorComponent_SR_SensorValues: required-interface=sensorComponent_SR_SensorValues
    behavior Ccounter_InternalBehavior: data-type-mapping=DataTypeMappingSet, handle-termination-and-restart=NO-SUPPORT
      ar-typed-per-instance-memorys:
        data StateOfHealth: sw-addr-method=CALIB, sw-calibration-access=READ-WRITE, type=StateOfHealth_ADT, init-value=constant-reference=StateOfHealth
      timing event calculateCoulomb_TimingEvent_100ms: start-on-event=calculateCoulomb, period=100
      per-instance-parameters:
        parameter data prototype nominalCapacity_C: sw-addr-method=CONST, sw-calibration-access=READ-ONLY, type=nominalCapacity_C_ADT, init-value=constant-reference=nominalCapacity_C  # Nominal Capacity of Cells calibration
        parameter data prototype stateOfHealth_C: sw-addr-method=CONST, sw-calibration-access=READ-ONLY, type=stateOfHealth_C_ADT, init-value=constant-reference=stateOfHealth_C  # state of health calibration
        parameter data prototype stateOfCharge_C: sw-addr-method=CONST, sw-calibration-access=READ-ONLY, type=stateOfCharge_C_ADT, init-value=constant-reference=stateOfCharge_C  # state of charge calibration
      runnable calculateCoulomb: sw-addr-method=CODE, symbol=Ccounter_calculateCoulomb
        data-receive-point-by-arguments:
          access DRP_RP_sensorComponent_SR_SensorValues_Current: accessed-variable=RP_sensorComponent_SR_SensorValues.Current
          access DRP_RP_sensorComponent_SR_SensorValues_Voltage: accessed-variable=RP_sensorComponent_SR_SensorValues.Voltage
        data-send-points:
          access DSP_PP_Ccounter_SR_NVMvalues_Ccounter_NVStateOfCharge: accessed-variable=PP_Ccounter_SR_NVMvalues.Ccounter_NVStateOfCharge
        parameter access PIPA_nominalCapacity_C: accessed-parameter=nominalCapacity_C
        parameter access PIPA_stateOfHealth_C: accessed-parameter=stateOfHealth_C
        parameter access PIPA_stateOfCharge_C: accessed-parameter=stateOfCharge_C
  swc implementation Ccounter_Implementation: programming-language=C, sw-version=1.0.0, vendor-id=100, behavior=Ccounter_InternalBehavior
    code-descriptors:
      code Ccounter_CodeDescriptor: artifact-descriptors=autosar-engineering-object={short-label=Ccounter, category=SWSRC}
    resource consumption Ccounter_RC
      13 x memory section:
        VAR_8: alignment=8, sw-addrmethod=VAR
        VAR_16: alignment=16, sw-addrmethod=VAR
        VAR_32: alignment=32, sw-addrmethod=VAR
        VAR_UNSPECIFIED: sw-addrmethod=VAR
        CALIB_8: alignment=8, sw-addrmethod=CALIB
        CALIB_16: alignment=16, sw-addrmethod=CALIB
        CALIB_32: alignment=32, sw-addrmethod=CALIB
        CALIB_UNSPECIFIED: sw-addrmethod=CALIB
        CONST_8: alignment=8, sw-addrmethod=CONST
        CONST_16: alignment=16, sw-addrmethod=CONST
        CONST_32: alignment=32, sw-addrmethod=CONST
        CONST_UNSPECIFIED: sw-addrmethod=CONST
        CODE: sw-addrmethod=CODE
package /Root_Package/SWCs/Core0/QM/Ccounter/Ccounter_SRInterfaces
  sender receiver interface Ccounter_SR_NVMvalues
    data Ccounter_NVStateOfCharge: sw-addr-method=VAR, sw-calibration-access=READ-WRITE, type=Ccounter_NVStateOfCharge_ADT  # state of charge written to NVM
package /Root_Package/SWCs/Core0/QM/sensorComponent
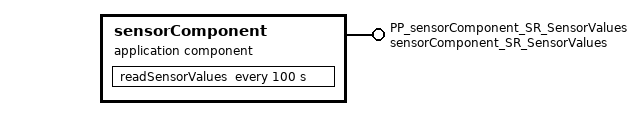
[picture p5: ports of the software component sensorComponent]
  application sw component type sensorComponent
    provide port PP_sensorComponent_SR_SensorValues: provided-interface=sensorComponent_SR_SensorValues
    behavior sensorComponent_InternalBehavior: data-type-mapping=DataTypeMappingSet, handle-termination-and-restart=NO-SUPPORT
      timing event readSensorValues_TimingEvent_100ms: start-on-event=readSensorValues, period=100
      runnable readSensorValues: sw-addr-method=CODE, symbol=sensorComponent_readSensorValues
        data-send-points:
          5 x access:
            DSP_PP_sensorComponent_SR_SensorValues_Current: accessed-variable=PP_sensorComponent_SR_SensorValues.Current
            DSP_PP_sensorComponent_SR_SensorValues_Voltage: accessed-variable=PP_sensorComponent_SR_SensorValues.Voltage
            DSP_PP_sensorComponent_SR_SensorValues_Cell_Voltage: accessed-variable=PP_sensorComponent_SR_SensorValues.Cell_Voltage
            DSP_PP_sensorComponent_SR_SensorValues_Current_Avg: accessed-variable=PP_sensorComponent_SR_SensorValues.Current_Avg
            DSP_PP_sensorComponent_SR_SensorValues_Voltage_OC: accessed-variable=PP_sensorComponent_SR_SensorValues.Voltage_OC
  swc implementation sensorComponent_Implementation: programming-language=C, sw-version=1.0.0, vendor-id=100, behavior=sensorComponent_InternalBehavior
    code-descriptors:
      code sensorComponent_CodeDescriptor: artifact-descriptors=autosar-engineering-object={short-label=sensorComponent, category=SWSRC}
    resource consumption sensorComponent_RC
      13 x memory section:
        VAR_8: alignment=8, sw-addrmethod=VAR
        VAR_16: alignment=16, sw-addrmethod=VAR
        VAR_32: alignment=32, sw-addrmethod=VAR
        VAR_UNSPECIFIED: sw-addrmethod=VAR
        CALIB_8: alignment=8, sw-addrmethod=CALIB
        CALIB_16: alignment=16, sw-addrmethod=CALIB
        CALIB_32: alignment=32, sw-addrmethod=CALIB
        CALIB_UNSPECIFIED: sw-addrmethod=CALIB
        CONST_8: alignment=8, sw-addrmethod=CONST
        CONST_16: alignment=16, sw-addrmethod=CONST
        CONST_32: alignment=32, sw-addrmethod=CONST
        CONST_UNSPECIFIED: sw-addrmethod=CONST
        CODE: sw-addrmethod=CODE
package /Root_Package/SWCs/Core0/QM/sensorComponent/sensorComponent_SRInterfaces
  sender receiver interface sensorComponent_SR_SensorValues
    5 x data, all with sw-addr-method=VAR, sw-calibration-access=READ-WRITE:
      Current: type=Current_ADT
      Voltage: type=Voltage_ADT
      Cell_Voltage: type=Cell_Voltage_ADT  # single cell voltage
      Current_Avg: type=Current_Avg_ADT  # average current measured
      Voltage_OC: type=Voltage_OC_ADT  # Open-Circuit voltage
package /Root_Package/SWCs/Core0/QM/RecalSOC
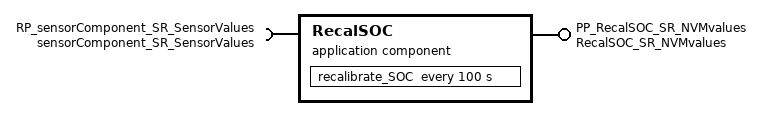
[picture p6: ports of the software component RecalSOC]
  application sw component type RecalSOC
    provide port PP_RecalSOC_SR_NVMvalues: provided-interface=RecalSOC_SR_NVMvalues
    require port RP_sensorComponent_SR_SensorValues: required-interface=sensorComponent_SR_SensorValues
    behavior RecalSOC_InternalBehavior: data-type-mapping=DataTypeMappingSet, handle-termination-and-restart=NO-SUPPORT
      timing event recalibrate_SOC_TimingEvent_100ms: start-on-event=recalibrate_SOC, period=100
      per-instance-parameters:
        parameter data prototype OCV_gra_C: sw-addr-method=CONST, sw-calibration-access=READ-ONLY, type=OCV_gra_C_ADT, init-value=constant-reference=OCV_gra_C  # Open-circuit voltage gradient
      runnable recalibrate_SOC: sw-addr-method=CODE, symbol=RecalSOC_recalibrate_SOC
        data-receive-point-by-arguments:
          access DRP_RP_sensorComponent_SR_SensorValues_Cell_Voltage: accessed-variable=RP_sensorComponent_SR_SensorValues.Cell_Voltage
          access DRP_RP_sensorComponent_SR_SensorValues_Current_Avg: accessed-variable=RP_sensorComponent_SR_SensorValues.Current_Avg
          access DRP_RP_sensorComponent_SR_SensorValues_Voltage_OC: accessed-variable=RP_sensorComponent_SR_SensorValues.Voltage_OC
        data-send-points:
          access DSP_PP_RecalSOC_SR_NVMvalues_RecalSOC_NVStateOfCharge: accessed-variable=PP_RecalSOC_SR_NVMvalues.RecalSOC_NVStateOfCharge
        parameter access PIPA_OCV_gra_C: accessed-parameter=OCV_gra_C
  swc implementation RecalSOC_Implementation: programming-language=C, sw-version=1.0.0, vendor-id=100, behavior=RecalSOC_InternalBehavior
    code-descriptors:
      code RecalSOC_CodeDescriptor: artifact-descriptors=autosar-engineering-object={short-label=RecalSOC, category=SWSRC}
    resource consumption RecalSOC_RC
      13 x memory section:
        VAR_8: alignment=8, sw-addrmethod=VAR
        VAR_16: alignment=16, sw-addrmethod=VAR
        VAR_32: alignment=32, sw-addrmethod=VAR
        VAR_UNSPECIFIED: sw-addrmethod=VAR
        CALIB_8: alignment=8, sw-addrmethod=CALIB
        CALIB_16: alignment=16, sw-addrmethod=CALIB
        CALIB_32: alignment=32, sw-addrmethod=CALIB
        CALIB_UNSPECIFIED: sw-addrmethod=CALIB
        CONST_8: alignment=8, sw-addrmethod=CONST
        CONST_16: alignment=16, sw-addrmethod=CONST
        CONST_32: alignment=32, sw-addrmethod=CONST
        CONST_UNSPECIFIED: sw-addrmethod=CONST
        CODE: sw-addrmethod=CODE
package /Root_Package/SWCs/Core0/QM/RecalSOC/RecalSOC_SRInterfaces
  sender receiver interface RecalSOC_SR_NVMvalues
    data RecalSOC_NVStateOfCharge: sw-addr-method=VAR, sw-calibration-access=READ-WRITE, type=RecalSOC_NVStateOfCharge_ADT  # state of charge written to NVM
package /Root_Package/SWCs/Core0/ASILB/CompE
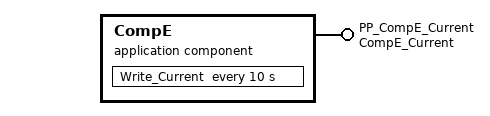
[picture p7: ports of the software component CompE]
  application sw component type CompE
    provide port PP_CompE_Current: provided-interface=CompE_Current
    behavior CompE_InternalBehavior: data-type-mapping=DataTypeMappingSet, handle-termination-and-restart=NO-SUPPORT
      timing event Write_Current_TimingEvent_10ms: start-on-event=Write_Current, period=10
      runnable Write_Current: sw-addr-method=CODE, symbol=CompE_Write_Current
        data-send-points:
          access DSP_PP_CompE_Current_Cureent: accessed-variable=PP_CompE_Current.Cureent
  swc implementation CompE_Implementation: programming-language=C, sw-version=1.0.0, vendor-id=100, behavior=CompE_InternalBehavior
    code-descriptors:
      code CompE_CodeDescriptor: artifact-descriptors=autosar-engineering-object={short-label=CompE, category=SWSRC}
    resource consumption CompE_RC
      13 x memory section:
        VAR_8: alignment=8, sw-addrmethod=VAR
        VAR_16: alignment=16, sw-addrmethod=VAR
        VAR_32: alignment=32, sw-addrmethod=VAR
        VAR_UNSPECIFIED: sw-addrmethod=VAR
        CALIB_8: alignment=8, sw-addrmethod=CALIB
        CALIB_16: alignment=16, sw-addrmethod=CALIB
        CALIB_32: alignment=32, sw-addrmethod=CALIB
        CALIB_UNSPECIFIED: sw-addrmethod=CALIB
        CONST_8: alignment=8, sw-addrmethod=CONST
        CONST_16: alignment=16, sw-addrmethod=CONST
        CONST_32: alignment=32, sw-addrmethod=CONST
        CONST_UNSPECIFIED: sw-addrmethod=CONST
        CODE: sw-addrmethod=CODE
package /Root_Package/SWCs/Core0/ASILB/CompE/CompE_SRInterfaces
  sender receiver interface CompE_Current
    data Cureent: sw-addr-method=VAR, sw-calibration-access=READ-WRITE, type=Cureent_ADT  # sdf
package /Root_Package/SWCs/Core1/QM/CompC
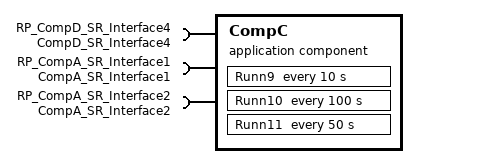
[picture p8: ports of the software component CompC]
  application sw component type CompC
    require port RP_CompD_SR_Interface4: required-interface=CompD_SR_Interface4
    require port RP_CompA_SR_Interface1: required-interface=CompA_SR_Interface1
    require port RP_CompA_SR_Interface2: required-interface=CompA_SR_Interface2
    behavior CompC_InternalBehavior: data-type-mapping=DataTypeMappingSet, handle-termination-and-restart=NO-SUPPORT
      init event Runn8_InitEvent: start-on-event=Runn8
      timing event Runn9_TimingEvent_10ms: start-on-event=Runn9, period=10
      timing event Runn10_TimingEvent_100ms: start-on-event=Runn10, period=100
      timing event Runn11_TimingEvent_50ms: start-on-event=Runn11, period=50
      4 x runnable, all with sw-addr-method=CODE:
        Runn{8..10}: symbol=CompC_Runn{8..10}
        Runn11: symbol=CompC_Runn11
          data-read-access:
            access DRA_RP_CompD_SR_Interface4_Element5: accessed-variable=RP_CompD_SR_Interface4.Element5
          data-receive-point-by-arguments:
            access DRP_RP_CompA_SR_Interface1_Element1: accessed-variable=RP_CompA_SR_Interface1.Element1
            access DRP_RP_CompA_SR_Interface2_Element2: accessed-variable=RP_CompA_SR_Interface2.Element2
  swc implementation CompC_Implementation: programming-language=C, sw-version=1.0.0, vendor-id=100, behavior=CompC_InternalBehavior
    code-descriptors:
      code CompC_CodeDescriptor: artifact-descriptors=autosar-engineering-object={short-label=CompC, category=SWSRC}
    resource consumption CompC_RC
      13 x memory section:
        VAR_8: alignment=8, sw-addrmethod=VAR
        VAR_16: alignment=16, sw-addrmethod=VAR
        VAR_32: alignment=32, sw-addrmethod=VAR
        VAR_UNSPECIFIED: sw-addrmethod=VAR
        CALIB_8: alignment=8, sw-addrmethod=CALIB
        CALIB_16: alignment=16, sw-addrmethod=CALIB
        CALIB_32: alignment=32, sw-addrmethod=CALIB
        CALIB_UNSPECIFIED: sw-addrmethod=CALIB
        CONST_8: alignment=8, sw-addrmethod=CONST
        CONST_16: alignment=16, sw-addrmethod=CONST
        CONST_32: alignment=32, sw-addrmethod=CONST
        CONST_UNSPECIFIED: sw-addrmethod=CONST
        CODE: sw-addrmethod=CODE
package /Root_Package/SWCs/Core1/ASILA/CompD
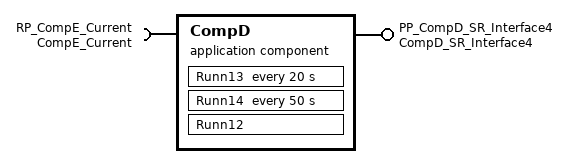
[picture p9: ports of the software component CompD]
  application sw component type CompD
    provide port PP_CompD_SR_Interface4: provided-interface=CompD_SR_Interface4
    require port RP_CompE_Current: required-interface=CompE_Current
    behavior CompD_InternalBehavior: data-type-mapping=DataTypeMappingSet, handle-termination-and-restart=NO-SUPPORT
      init event Runn12_InitEvent: start-on-event=Runn12
      timing event Runn13_TimingEvent_20ms: start-on-event=Runn13, period=20
      timing event Runn14_TimingEvent_50ms: start-on-event=Runn14, period=50
      runnable Runn12: sw-addr-method=CODE, symbol=CompD_Runn12
      runnable Runn13: sw-addr-method=CODE, symbol=CompD_Runn13
      runnable Runn14: sw-addr-method=CODE, symbol=CompD_Runn14
        data-receive-point-by-arguments:
          access DRP_RP_CompE_Current_Cureent: accessed-variable=RP_CompE_Current.Cureent
        data-write-access:
          access DWA_PP_CompD_SR_Interface4_Element5: accessed-variable=PP_CompD_SR_Interface4.Element5
  swc implementation CompD_Implementation: programming-language=C, sw-version=1.0.0, vendor-id=100, behavior=CompD_InternalBehavior
    code-descriptors:
      code CompD_CodeDescriptor: artifact-descriptors=autosar-engineering-object={short-label=CompD, category=SWSRC}
    resource consumption CompD_RC
      13 x memory section:
        VAR_8: alignment=8, sw-addrmethod=VAR
        VAR_16: alignment=16, sw-addrmethod=VAR
        VAR_32: alignment=32, sw-addrmethod=VAR
        VAR_UNSPECIFIED: sw-addrmethod=VAR
        CALIB_8: alignment=8, sw-addrmethod=CALIB
        CALIB_16: alignment=16, sw-addrmethod=CALIB
        CALIB_32: alignment=32, sw-addrmethod=CALIB
        CALIB_UNSPECIFIED: sw-addrmethod=CALIB
        CONST_8: alignment=8, sw-addrmethod=CONST
        CONST_16: alignment=16, sw-addrmethod=CONST
        CONST_32: alignment=32, sw-addrmethod=CONST
        CONST_UNSPECIFIED: sw-addrmethod=CONST
        CODE: sw-addrmethod=CODE
package /Root_Package/SWCs/Core1/ASILA/CompD/CompD_SRInterfaces
  sender receiver interface CompD_SR_Interface4
    data Element5: sw-addr-method=VAR, sw-calibration-access=READ-WRITE, type=Element5_ADT_Columns  # Test5
package /Root_Package/TopLevelComposition
  composition sw component type TopLevelComposition
    component Core0: type=Core0
    component Core1: type=Core1
    connect Core0.PP_CompA_SR_Interface1 -> Core1.RP_CompA_SR_Interface1
    connect Core0.PP_CompA_SR_Interface2 -> Core1.RP_CompA_SR_Interface2
    connect Core0.PP_CompE_Current -> Core1.RP_CompE_Current
package /Root_Package/TopLevelComposition/CoreCompositions
  composition sw component type Core0
    8 x provide port:
      PP_CompA_SR_Interface1: provided-interface=CompA_SR_Interface1
      PP_CompA_SR_Interface2: provided-interface=CompA_SR_Interface2
      PP_Message{1..3}: provided-interface=Message{1..3}
      PP_Ccounter_SR_NVMvalues: provided-interface=Ccounter_SR_NVMvalues
      PP_RecalSOC_SR_NVMvalues: provided-interface=RecalSOC_SR_NVMvalues
      PP_CompE_Current: provided-interface=CompE_Current
    4 x require port:
      RP_Message{4..6}: required-interface=Message{4..6}
      RP_sensorComponent_SR_SensorValues: required-interface=sensorComponent_SR_SensorValues
    component Core0_QM: type=Core0_QM
    component Core0_ASILB: type=Core0_ASILB
    delegate Core0_QM.PP_CompA_SR_Interface1 <-> outer port Core0/PP_CompA_SR_Interface1
    delegate Core0_QM.PP_CompA_SR_Interface2 <-> outer port Core0/PP_CompA_SR_Interface2
    delegate Core0_QM.PP_Message{1..3} <-> outer port Core0/PP_Message{1..3}
    delegate Core0_QM.PP_Ccounter_SR_NVMvalues <-> outer port Core0/PP_Ccounter_SR_NVMvalues
    delegate Core0_QM.PP_RecalSOC_SR_NVMvalues <-> outer port Core0/PP_RecalSOC_SR_NVMvalues
    delegate Core0_ASILB.PP_CompE_Current <-> outer port Core0/PP_CompE_Current
    delegate Core0_QM.RP_Message{4..6} <-> outer port Core0/RP_Message{4..6}
    delegate Core0_QM.RP_sensorComponent_SR_SensorValues <-> outer port Core0/RP_sensorComponent_SR_SensorValues
  composition sw component type Core1
    require port RP_CompA_SR_Interface1: required-interface=CompA_SR_Interface1
    require port RP_CompA_SR_Interface2: required-interface=CompA_SR_Interface2
    require port RP_CompE_Current: required-interface=CompE_Current
    component Core1_QM: type=Core1_QM
    component Core1_ASILA: type=Core1_ASILA
    connect Core1_ASILA.PP_CompD_SR_Interface4 -> Core1_QM.RP_CompD_SR_Interface4
    delegate Core1_QM.RP_CompA_SR_Interface1 <-> outer port Core1/RP_CompA_SR_Interface1
    delegate Core1_QM.RP_CompA_SR_Interface2 <-> outer port Core1/RP_CompA_SR_Interface2
    delegate Core1_ASILA.RP_CompE_Current <-> outer port Core1/RP_CompE_Current
package /Root_Package/TopLevelComposition/ASILCompositions
  composition sw component type Core0_QM
    7 x provide port:
      PP_CompA_SR_Interface1: provided-interface=CompA_SR_Interface1
      PP_CompA_SR_Interface2: provided-interface=CompA_SR_Interface2
      PP_Message{1..3}: provided-interface=Message{1..3}
      PP_Ccounter_SR_NVMvalues: provided-interface=Ccounter_SR_NVMvalues
      PP_RecalSOC_SR_NVMvalues: provided-interface=RecalSOC_SR_NVMvalues
    4 x require port:
      RP_Message{4..6}: required-interface=Message{4..6}
      RP_sensorComponent_SR_SensorValues: required-interface=sensorComponent_SR_SensorValues
    7 x component:
      CompA: type=CompA
      CompB: type=CompB
      InputComp: type=InputComp
      OutputComp: type=OutputComp
      Ccounter: type=Ccounter
      sensorComponent: type=sensorComponent
      RecalSOC: type=RecalSOC
    delegate CompA.PP_CompA_SR_Interface1 <-> outer port Core0_QM/PP_CompA_SR_Interface1
    delegate CompA.PP_CompA_SR_Interface2 <-> outer port Core0_QM/PP_CompA_SR_Interface2
    connect CompB.PP_CompB_SR_Interface3 -> CompA.RP_CompB_SR_Interface3
    connect CompB.PS_CompB_CS_Interface1 -> CompA.RC_CompB_CS_Interface1
    connect InputComp.PP_InputComp_SR_CANInfo -> OutputComp.RP_InputComp_SR_CANInfo
    delegate OutputComp.PP_Message{1..3} <-> outer port Core0_QM/PP_Message{1..3}
    delegate Ccounter.PP_Ccounter_SR_NVMvalues <-> outer port Core0_QM/PP_Ccounter_SR_NVMvalues
    connect sensorComponent.PP_sensorComponent_SR_SensorValues -> Ccounter.RP_sensorComponent_SR_SensorValues
    delegate RecalSOC.PP_RecalSOC_SR_NVMvalues <-> outer port Core0_QM/PP_RecalSOC_SR_NVMvalues
    delegate InputComp.RP_Message{4..6} <-> outer port Core0_QM/RP_Message{4..6}
    delegate RecalSOC.RP_sensorComponent_SR_SensorValues <-> outer port Core0_QM/RP_sensorComponent_SR_SensorValues
  composition sw component type Core0_ASILB
    provide port PP_CompE_Current: provided-interface=CompE_Current
    component CompE: type=CompE
    delegate CompE.PP_CompE_Current <-> outer port Core0_ASILB/PP_CompE_Current
  composition sw component type Core1_QM
    require port RP_CompD_SR_Interface4: required-interface=CompD_SR_Interface4
    require port RP_CompA_SR_Interface1: required-interface=CompA_SR_Interface1
    require port RP_CompA_SR_Interface2: required-interface=CompA_SR_Interface2
    component CompC: type=CompC
    delegate CompC.RP_CompD_SR_Interface4 <-> outer port Core1_QM/RP_CompD_SR_Interface4
    delegate CompC.RP_CompA_SR_Interface1 <-> outer port Core1_QM/RP_CompA_SR_Interface1
    delegate CompC.RP_CompA_SR_Interface2 <-> outer port Core1_QM/RP_CompA_SR_Interface2
  composition sw component type Core1_ASILA
    provide port PP_CompD_SR_Interface4: provided-interface=CompD_SR_Interface4
    require port RP_CompE_Current: required-interface=CompE_Current
    component CompD: type=CompD
    delegate CompD.PP_CompD_SR_Interface4 <-> outer port Core1_ASILA/PP_CompD_SR_Interface4
    delegate CompD.RP_CompE_Current <-> outer port Core1_ASILA/RP_CompE_Current
package /CANCatalog/Cluster
  can cluster CAN_Bus_Cluster: baudrate=500000, protocol-name=CAN
    can physical channel CAN_Bus_Channel: comm-connectors=[ECU1_CanCommunicationConnector, ECU2_CanCommunicationConnector, ECU3_CanCommunicationConnector]
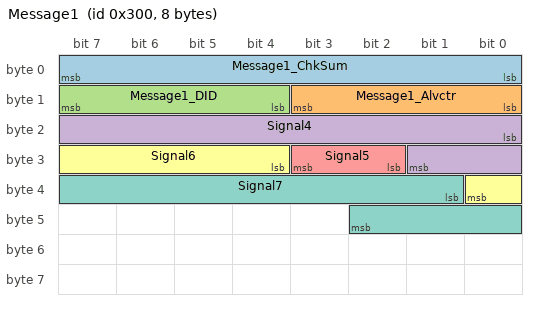
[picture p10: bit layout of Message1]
      frame Message1: id 0x300, from ECU1, to ECU2, frame-length=8, can-addressing-mode=EXTENDED, can-frame-rx-behavior=CAN-FD, can-frame-tx-behavior=CAN-FD
        pdu Message1: length=8, transmission-mode-true-timing=cyclic-timing=time-period=10, unused-bit-pattern=255
          mapping Message1_Message1Group: i-signal-group=Message1, packing-byte-order=little-endian
          signal Message1_ChkSum: start 0, 8 bit, little-endian, data-type-policy=OVERRIDE, base-type=Message1_ChkSum_sw_basetype, compu {phys=raw*10+10}, range raw 0..50
          signal Message1_Alvctr: start 8, 4 bit, little-endian, data-type-policy=OVERRIDE, base-type=Message1_Alvctr_sw_basetype, compu {phys=0.5}, range raw -100..100, unit=NoUnit
          signal Message1_DID: start 12, 4 bit, little-endian, data-type-policy=OVERRIDE, base-type=Message1_DID_sw_basetype, compu {phys=2}, range raw 0..1000, unit=NoUnit
          signal Signal4: start 16, 10 bit, little-endian, data-type-policy=OVERRIDE, base-type=Signal4_sw_basetype, compu {phys=raw*100+1}, range raw -5000..5000, unit=V
          signal Signal5: start 26, 2 bit, little-endian, data-type-policy=OVERRIDE, base-type=Signal5_sw_basetype, compu {identical}, range raw 0..100, unit=A
          signal Signal6: start 28, 5 bit, little-endian, data-type-policy=OVERRIDE, base-type=Signal6_sw_basetype, compu {identical}, range raw 0..100, unit=°C
          signal Signal7: start 33, 10 bit, little-endian, data-type-policy=OVERRIDE, base-type=Signal7_sw_basetype, compu {identical}, range raw 0..5000, unit=°F
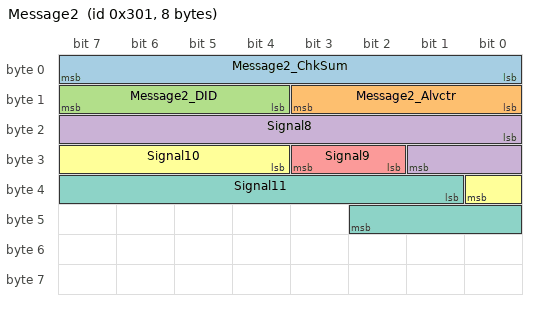
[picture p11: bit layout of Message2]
      frame Message2: id 0x301, from ECU1, to ECU2, frame-length=8, can-addressing-mode=EXTENDED, can-frame-rx-behavior=CAN-FD, can-frame-tx-behavior=CAN-FD
        pdu Message2: length=8, transmission-mode-true-timing=cyclic-timing=time-period=10, unused-bit-pattern=255
          mapping Message2_Message2Group: i-signal-group=Message2, packing-byte-order=little-endian
          signal Message2_ChkSum: start 0, 8 bit, little-endian, data-type-policy=OVERRIDE, base-type=Message2_ChkSum_sw_basetype, compu {phys=raw*10+10}, range raw 0..50, unit=NoUnit
          signal Message2_Alvctr: start 8, 4 bit, little-endian, data-type-policy=OVERRIDE, base-type=Message2_Alvctr_sw_basetype, compu {phys=0.5}, range raw -100..100, unit=NoUnit
          signal Message2_DID: start 12, 4 bit, little-endian, data-type-policy=OVERRIDE, base-type=Message2_DID_sw_basetype, compu {phys=2}, range raw 0..1000, unit=NoUnit
          signal Signal8: start 16, 10 bit, little-endian, data-type-policy=OVERRIDE, base-type=Signal8_sw_basetype, compu {phys=raw*100+1}, range raw -5000..5000, unit=V
          signal Signal9: start 26, 2 bit, little-endian, data-type-policy=OVERRIDE, base-type=Signal9_sw_basetype, compu {identical}, range raw 0..100, unit=A
          signal Signal10: start 28, 5 bit, little-endian, data-type-policy=OVERRIDE, base-type=Signal10_sw_basetype, compu {identical}, range raw 0..100, unit=°C
          signal Signal11: start 33, 10 bit, little-endian, data-type-policy=OVERRIDE, base-type=Signal11_sw_basetype, compu {identical}, range raw 0..5000, unit=°F
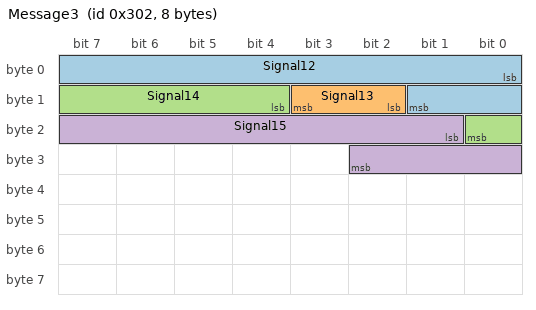
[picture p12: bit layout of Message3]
      frame Message3: id 0x302, from ECU1, to ECU2, frame-length=8, can-addressing-mode=EXTENDED, can-frame-rx-behavior=CAN-FD, can-frame-tx-behavior=CAN-FD
        pdu Message3: length=8, transmission-mode-true-timing=cyclic-timing=time-period=10, unused-bit-pattern=256
          signal Signal12: start 0, 10 bit, little-endian, data-type-policy=OVERRIDE, base-type=Signal12_sw_basetype, compu {phys=raw*100+1}, range raw -5000..5000, unit=V, to ECU2
          signal Signal13: start 10, 2 bit, little-endian, data-type-policy=OVERRIDE, base-type=Signal13_sw_basetype, compu {identical}, range raw 0..100, unit=A, to ECU2
          signal Signal14: start 12, 5 bit, little-endian, data-type-policy=OVERRIDE, base-type=Signal14_sw_basetype, compu {identical}, range raw 0..100, unit=°C, to ECU2
          signal Signal15: start 17, 10 bit, little-endian, data-type-policy=OVERRIDE, base-type=Signal15_sw_basetype, compu {identical}, range raw 0..5000, unit=°F, to ECU2
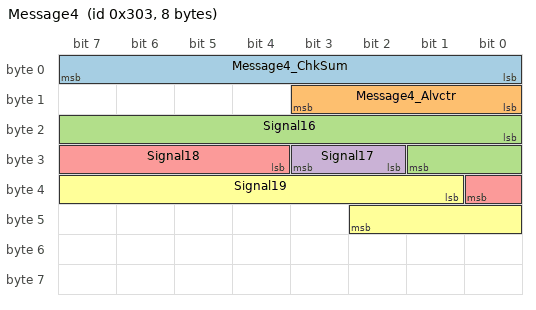
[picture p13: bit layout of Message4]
      frame Message4: id 0x303, from ECU2, to ECU1, frame-length=8, can-addressing-mode=EXTENDED, can-frame-rx-behavior=CAN-FD, can-frame-tx-behavior=CAN-FD
        pdu Message4: length=8, transmission-mode-true-timing=cyclic-timing=time-period=10, unused-bit-pattern=257
          mapping Message4_Message4Group: i-signal-group=Message4, packing-byte-order=little-endian
          signal Message4_ChkSum: start 0, 8 bit, little-endian, data-type-policy=OVERRIDE, base-type=Message4_ChkSum_sw_basetype, compu {phys=raw*10+10}, range raw 0..50, unit=NoUnit
          signal Message4_Alvctr: start 8, 4 bit, little-endian, data-type-policy=OVERRIDE, base-type=Message4_Alvctr_sw_basetype, compu {phys=0.5}, range raw -100..100, unit=NoUnit
          mapping Message4_Message4_DID: i-signal=Message4_DID1, packing-byte-order=little-endian, start-position=12
          signal Signal16: start 16, 10 bit, little-endian, data-type-policy=OVERRIDE, base-type=Signal16_sw_basetype, compu {phys=raw*100+1}, range raw -5000..5000, unit=V
          signal Signal17: start 26, 2 bit, little-endian, data-type-policy=OVERRIDE, base-type=Signal17_sw_basetype, compu {identical}, range raw 0..100, unit=A
          signal Signal18: start 28, 5 bit, little-endian, data-type-policy=OVERRIDE, base-type=Signal18_sw_basetype, compu {identical}, range raw 0..100, unit=°C
          signal Signal19: start 33, 10 bit, little-endian, data-type-policy=OVERRIDE, base-type=Signal19_sw_basetype, compu {identical}, range raw 0..5000, unit=°F
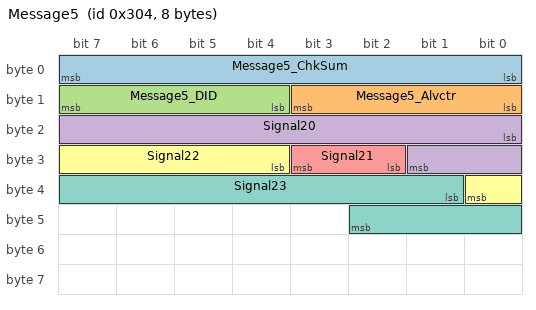
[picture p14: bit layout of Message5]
      frame Message5: id 0x304, from ECU2, to ECU1, frame-length=8, can-addressing-mode=EXTENDED, can-frame-rx-behavior=CAN-FD, can-frame-tx-behavior=CAN-FD
        pdu Message5: length=8, transmission-mode-true-timing=cyclic-timing=time-period=10, unused-bit-pattern=258
          mapping Message5_Message5Group: i-signal-group=Message5, packing-byte-order=little-endian
          signal Message5_ChkSum: start 0, 8 bit, little-endian, data-type-policy=OVERRIDE, base-type=Message5_ChkSum_sw_basetype, compu {phys=raw*10+10}, range raw 0..50, unit=NoUnit
          signal Message5_Alvctr: start 8, 4 bit, little-endian, data-type-policy=OVERRIDE, base-type=Message5_Alvctr_sw_basetype, compu {phys=0.5}, range raw -100..100, unit=NoUnit
          signal Message5_DID: start 12, 4 bit, little-endian, data-type-policy=OVERRIDE, base-type=Message5_DID_sw_basetype, compu {phys=2}, range raw 0..1000, unit=NoUnit
          signal Signal20: start 16, 10 bit, little-endian, data-type-policy=OVERRIDE, base-type=Signal20_sw_basetype, compu {phys=raw*100+1}, range raw -5000..5000, unit=V  # Signal19
          signal Signal21: start 26, 2 bit, little-endian, data-type-policy=OVERRIDE, base-type=Signal21_sw_basetype, compu {identical}, range raw 0..100, unit=A  # Signal20
          signal Signal22: start 28, 5 bit, little-endian, data-type-policy=OVERRIDE, base-type=Signal22_sw_basetype, compu {identical}, range raw 0..100, unit=°C  # Signal21
          signal Signal23: start 33, 10 bit, little-endian, data-type-policy=OVERRIDE, base-type=Signal23_sw_basetype, compu {identical}, range raw 0..5000, unit=°F  # Signal22
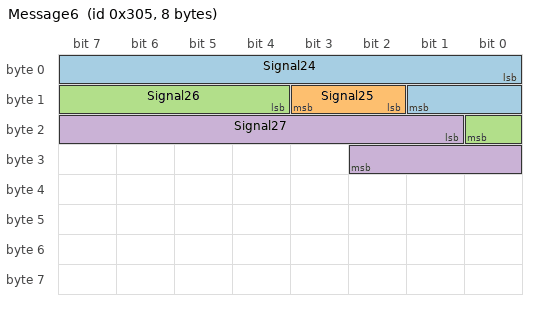
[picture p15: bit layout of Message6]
      frame Message6: id 0x305, from ECU2, to ECU1, frame-length=8, can-addressing-mode=EXTENDED, can-frame-rx-behavior=CAN-FD, can-frame-tx-behavior=CAN-FD
        pdu Message6: length=8, transmission-mode-true-timing=cyclic-timing=time-period=10, unused-bit-pattern=259
          signal Signal24: start 0, 10 bit, little-endian, data-type-policy=OVERRIDE, base-type=Signal24_sw_basetype, compu {phys=raw*100+1}, range raw -5000..5000, unit=V, to ECU1  # Signal23
          signal Signal25: start 10, 2 bit, little-endian, data-type-policy=OVERRIDE, base-type=Signal25_sw_basetype, compu {identical}, range raw 0..100, unit=A, to ECU1  # Signal24
          signal Signal26: start 12, 5 bit, little-endian, data-type-policy=OVERRIDE, base-type=Signal26_sw_basetype, compu {identical}, range raw 0..100, unit=°C, to ECU1  # Signal25
          signal Signal27: start 17, 10 bit, little-endian, data-type-policy=OVERRIDE, base-type=Signal27_sw_basetype, compu {identical}, range raw 0..5000, unit=°F, to ECU1  # Signal26
package /CANCatalog/DataTypes
  base type Message1_ChkSum_sw_basetype: category=FIXED_LENGTH, base-type-size=8, base-type-encoding=NONE, native-declaration=unsigned char
  base type Message1_Alvctr_sw_basetype: category=FIXED_LENGTH, base-type-size=16, base-type-encoding=2C, native-declaration=short
  base type Message1_DID_sw_basetype: category=FIXED_LENGTH, base-type-size=16, base-type-encoding=NONE, native-declaration=unsigned short
  base type Signal4_sw_basetype: category=FIXED_LENGTH, base-type-size=16, base-type-encoding=2C, native-declaration=short
  base type Signal5_sw_basetype: category=FIXED_LENGTH, base-type-size=8, base-type-encoding=NONE, native-declaration=unsigned char
  base type Signal6_sw_basetype: category=FIXED_LENGTH, base-type-size=8, base-type-encoding=NONE, native-declaration=unsigned char
  base type Signal7_sw_basetype: category=FIXED_LENGTH, base-type-size=16, base-type-encoding=NONE, native-declaration=unsigned short
  base type Message2_ChkSum_sw_basetype: category=FIXED_LENGTH, base-type-size=8, base-type-encoding=NONE, native-declaration=unsigned char
  base type Message2_Alvctr_sw_basetype: category=FIXED_LENGTH, base-type-size=16, base-type-encoding=2C, native-declaration=short
  base type Message2_DID_sw_basetype: category=FIXED_LENGTH, base-type-size=16, base-type-encoding=NONE, native-declaration=unsigned short
  base type Signal8_sw_basetype: category=FIXED_LENGTH, base-type-size=16, base-type-encoding=2C, native-declaration=short
  base type Signal9_sw_basetype: category=FIXED_LENGTH, base-type-size=8, base-type-encoding=NONE, native-declaration=unsigned char
  base type Signal10_sw_basetype: category=FIXED_LENGTH, base-type-size=8, base-type-encoding=NONE, native-declaration=unsigned char
  base type Signal11_sw_basetype: category=FIXED_LENGTH, base-type-size=16, base-type-encoding=NONE, native-declaration=unsigned short
  base type Signal12_sw_basetype: category=FIXED_LENGTH, base-type-size=16, base-type-encoding=2C, native-declaration=short
  base type Signal13_sw_basetype: category=FIXED_LENGTH, base-type-size=8, base-type-encoding=NONE, native-declaration=unsigned char
  base type Signal14_sw_basetype: category=FIXED_LENGTH, base-type-size=8, base-type-encoding=NONE, native-declaration=unsigned char
  base type Signal15_sw_basetype: category=FIXED_LENGTH, base-type-size=16, base-type-encoding=NONE, native-declaration=unsigned short
  base type Message4_ChkSum_sw_basetype: category=FIXED_LENGTH, base-type-size=8, base-type-encoding=NONE, native-declaration=unsigned char
  base type Message4_Alvctr_sw_basetype: category=FIXED_LENGTH, base-type-size=16, base-type-encoding=2C, native-declaration=short
  base type Message4_DID_sw_basetype: category=FIXED_LENGTH, base-type-size=16, base-type-encoding=NONE, native-declaration=unsigned short
  base type Signal16_sw_basetype: category=FIXED_LENGTH, base-type-size=16, base-type-encoding=2C, native-declaration=short
  base type Signal17_sw_basetype: category=FIXED_LENGTH, base-type-size=8, base-type-encoding=NONE, native-declaration=unsigned char
  base type Signal18_sw_basetype: category=FIXED_LENGTH, base-type-size=8, base-type-encoding=NONE, native-declaration=unsigned char
  base type Signal19_sw_basetype: category=FIXED_LENGTH, base-type-size=16, base-type-encoding=NONE, native-declaration=unsigned short
  base type Message5_ChkSum_sw_basetype: category=FIXED_LENGTH, base-type-size=8, base-type-encoding=NONE, native-declaration=unsigned char
  base type Message5_Alvctr_sw_basetype: category=FIXED_LENGTH, base-type-size=16, base-type-encoding=2C, native-declaration=short
  base type Message5_DID_sw_basetype: category=FIXED_LENGTH, base-type-size=16, base-type-encoding=NONE, native-declaration=unsigned short
  base type Signal20_sw_basetype: category=FIXED_LENGTH, base-type-size=16, base-type-encoding=2C, native-declaration=short
  base type Signal21_sw_basetype: category=FIXED_LENGTH, base-type-size=8, base-type-encoding=NONE, native-declaration=unsigned char
  base type Signal22_sw_basetype: category=FIXED_LENGTH, base-type-size=8, base-type-encoding=NONE, native-declaration=unsigned char
  base type Signal23_sw_basetype: category=FIXED_LENGTH, base-type-size=16, base-type-encoding=NONE, native-declaration=unsigned short
  base type Signal24_sw_basetype: category=FIXED_LENGTH, base-type-size=16, base-type-encoding=2C, native-declaration=short
  base type Signal25_sw_basetype: category=FIXED_LENGTH, base-type-size=8, base-type-encoding=NONE, native-declaration=unsigned char
  base type Signal26_sw_basetype: category=FIXED_LENGTH, base-type-size=8, base-type-encoding=NONE, native-declaration=unsigned char
  base type Signal27_sw_basetype: category=FIXED_LENGTH, base-type-size=16, base-type-encoding=NONE, native-declaration=unsigned short
package /CANCatalog/ECUs
  ecu instance ECU1: diagnostic-address=0, sleep-mode-supported=true, wake-up-over-bus-supported=true  # ECU Desc 1
    can communication controller ECU1_CanCommunicationController
    can communication connector ECU1_CanCommunicationConnector: comm-controller=ECU1_CanCommunicationController
  ecu instance ECU2: diagnostic-address=1, sleep-mode-supported=true, wake-up-over-bus-supported=true  # ECU Desc 2
    can communication controller ECU2_CanCommunicationController
    can communication connector ECU2_CanCommunicationConnector: comm-controller=ECU2_CanCommunicationController
  ecu instance ECU3: diagnostic-address=2, sleep-mode-supported=true, wake-up-over-bus-supported=true  # ECU Desc 3
    can communication controller ECU3_CanCommunicationController
    can communication connector ECU3_CanCommunicationConnector: comm-controller=ECU3_CanCommunicationController
package /CANCatalog/ISignals
  i signal Message4_DID: data-type-policy=OVERRIDE, length=4, base-type=Message4_DID_sw_basetype, system-signal=Message4_DID
package /CANCatalog/SystemSignals
  system signal Message4_DID: compu {phys=2}, range raw 0..1000, unit=NoUnit
package /CANCatalog/ISignalsGroup
  4 x i signal group:
    Message1: i-signal=[Message1_ChkSum, Message1_Alvctr, Message1_DID, Signal4, Signal5, Signal6, Signal7], system-signal-group=Message1
    Message2: i-signal=[Message2_ChkSum, Message2_Alvctr, Message2_DID, Signal8, Signal9, Signal10, Signal11], system-signal-group=Message2
    Message4: i-signal=[Message4_ChkSum, Message4_Alvctr, Message4_DID, Signal16, Signal17, Signal18, Signal19], system-signal-group=Message4
    Message5: i-signal=[Message5_ChkSum, Message5_Alvctr, Message5_DID, Signal20, Signal21, Signal22, Signal23], system-signal-group=Message5
